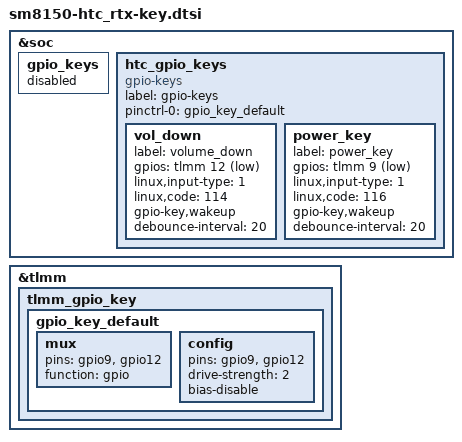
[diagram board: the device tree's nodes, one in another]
&soc {
	gpio_keys {
		status = "disabled";
	};
};

&soc {
	htc_gpio_keys {
		compatible = "gpio-keys";
		label = "gpio-keys";

		pinctrl-names = "default";
		pinctrl-0 = <&gpio_key_default>;

		vol_down {
			label = "volume_down";
			gpios = <&tlmm 12 GPIO_ACTIVE_LOW>;
			linux,input-type = <1>;
			linux,code = <114>;
			gpio-key,wakeup;
			debounce-interval = <20>;
		};

		power_key {
			label = "power_key";
			gpios = <&tlmm 9 GPIO_ACTIVE_LOW>;
			linux,input-type = <1>;
			linux,code = <116>;
			gpio-key,wakeup;
			debounce-interval = <20>;
		};
	};
};

&tlmm {
	tlmm_gpio_key {
		gpio_key_default: gpio_key_default {
			mux {
				pins = "gpio9", "gpio12";
				function = "gpio";
			};
			config {
				pins = "gpio9", "gpio12";
				drive-strength = <2>;
				bias-disable;
			};
		};
	};
};

&soc {
	gpio_keys {
		/delete-node/ vol_up;
	};
};
